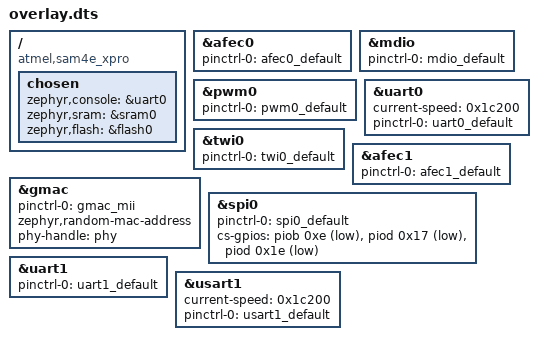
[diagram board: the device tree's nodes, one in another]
/ {
	compatible = "atmel,sam4e_xpro", "atmel,sam4e16e", "atmel,sam4e";
	chosen {
		zephyr,console = &uart0;
		zephyr,sram = &sram0;
		zephyr,flash = &flash0;
	};
};
&afec0{
	status = "okay";
	pinctrl-0 = < &afec0_default >;
	pinctrl-names = "default";
};
&mdio{
	status = "okay";
	pinctrl-0 = < &mdio_default >;
	pinctrl-names = "default";
};
&pwm0{
	status = "okay";
	pinctrl-0 = < &pwm0_default >;
	pinctrl-names = "default";
};
&uart0{
	status = "okay";
	current-speed = < 0x1c200 >;
	pinctrl-0 = < &uart0_default >;
	pinctrl-names = "default";
};
&twi0{
	status = "okay";
	pinctrl-0 = < &twi0_default >;
	pinctrl-names = "default";
};
&afec1{
	status = "okay";
	pinctrl-0 = < &afec1_default >;
	pinctrl-names = "default";
};
&gmac{
	status = "okay";
	pinctrl-0 = < &gmac_mii >;
	pinctrl-names = "default";
	zephyr,random-mac-address;
	phy-handle = < &phy >;
};
&spi0{
	status = "okay";
	pinctrl-0 = < &spi0_default >;
	pinctrl-names = "default";
	cs-gpios = < &piob 0xe 0x1 >, < &piod 0x17 0x1 >, < &piod 0x1e 0x1 >;
};
&uart1{
	pinctrl-0 = < &uart1_default >;
	pinctrl-names = "default";
};
&usart1{
	status = "okay";
	current-speed = < 0x1c200 >;
	pinctrl-0 = < &usart1_default >;
	pinctrl-names = "default";
};
